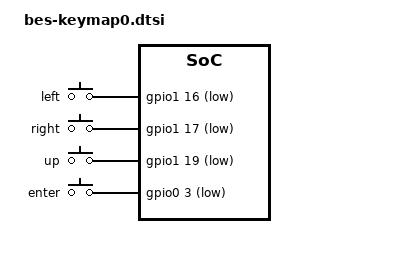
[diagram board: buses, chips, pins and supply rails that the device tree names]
/*
 * Copyright (C) 2012 Texas Instruments Incorporated - http://www.ti.com/
 *
 * This program is free software; you can redistribute it and/or modify
 * it under the terms of the GNU General Public License version 2 as
 * published by the Free Software Foundation.
 */

&ocp {
	P9_15_pinmux {
		/* gpio1[16] */
		status = "disabled";
	};
	P9_16_pinmux {
		/* gpio1[19] */
		status = "disabled";
	};
	P9_21_pinmux {
		/* gpio0[3] */
		status = "disabled";
	};
	P9_23_pinmux {
		/* gpio1[17] */
		status = "disabled";
	};
	/* AWH - Conflict with audio revb cape! gpio3[16] */
	/*P9_30_pinmux {
		status = "disabled";
	};*/
};

&am33xx_pinmux {
	bes_keymap0_pins: pinmux_bes_keymap0_pins {
		pinctrl-single,pins = <
			0x040 0x2f  /* KEY_LEFT gpmc_a0.gpio1_16, INPUT | PULLDIS | MODE7 */
			0x044 0x2f  /* KEY_RIGHT gpmc_a1.gpio1_17, INPUT | PULLDIS | MODE7 */
			0x04c 0x2f  /* KEY_UP gpmc_a3.gpio1_19, INPUT | PULLDIS | MODE7 */
			/* AWH - Conflict 0x198 0x2f*/  /* KEY_DOWN mcasp0_axr0.gpio3_16, INPUT | PULLDIS | MODE7 */
			0x154 0x2f  /* KEY_ENTER spi0_d0.gpio0_3, INPUT | PULLDIS | MODE7 */
		>;
	};
};

/ {
	gpio_keys {
		compatible = "gpio-keys";
		pinctrl-names = "default";
		pinctrl-0 = <&bes_keymap0_pins>;

		#address-cells = <1>;
		#size-cells = <0>;

		button@1 {
			debounce_interval = <50>;
			linux,code = <105>;
			label = "left";
			gpios = <&gpio1 16 0x1>;
			gpio-key,wakeup;
			autorepeat;
		};
		button@2 {
			debounce_interval = <50>;
			linux,code = <106>;
			label = "right";
			gpios = <&gpio1 17 0x1>;
			gpio-key,wakeup;
			autorepeat;
		};
		button@3 {
			debounce_interval = <50>;
			linux,code = <103>;
			label = "up";
			gpios = <&gpio1 19 0x1>;
			gpio-key,wakeup;
			autorepeat;
		};
		/* AWH - BES - Conflict with audio cape! */
		/*button@4 {
			debounce_interval = <50>;
			linux,code = <108>;
			label = "down";
			gpios = <&gpio3 16 0x1>;
			gpio-key,wakeup;
			autorepeat;
		};*/
		button@5 {
			debounce_interval = <50>;
			linux,code = <28>;
			label = "enter";
			gpios = <&gpio0 3 0x1>;
			gpio-key,wakeup;
		};
	};
};
